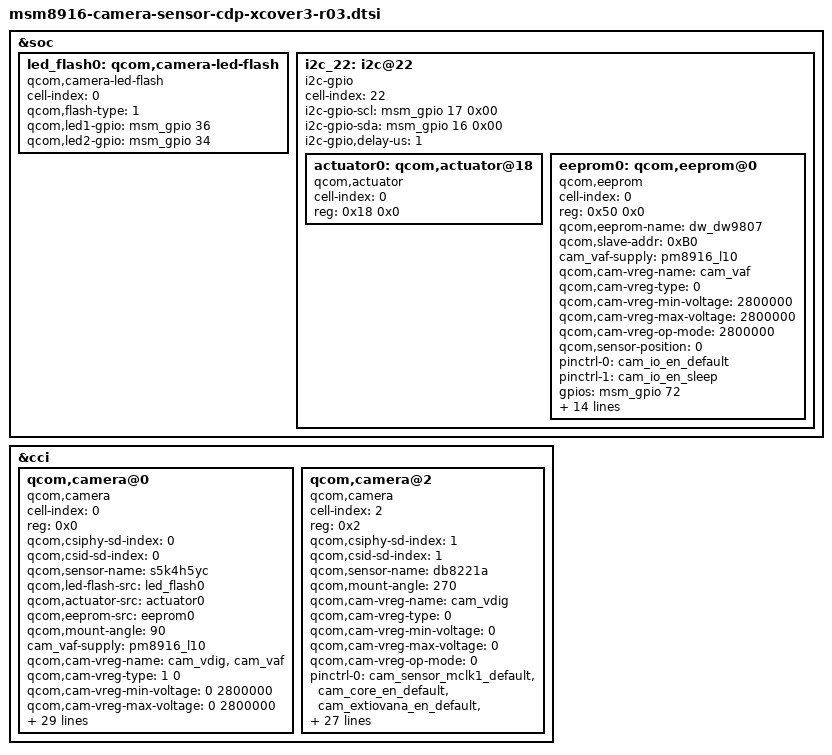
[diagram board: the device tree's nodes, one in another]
/*
 * Copyright (c) 2014, The Linux Foundation. All rights reserved.
 *
 * This program is free software; you can redistribute it and/or modify
 * it under the terms of the GNU General Public License version 2 and
 * only version 2 as published by the Free Software Foundation.
 *
 * This program is distributed in the hope that it will be useful,
 * but WITHOUT ANY WARRANTY; without even the implied warranty of
 * MERCHANTABILITY or FITNESS FOR A PARTICULAR PURPOSE.  See the
 * GNU General Public License for more details.
 */

&soc {
    led_flash0: qcom,camera-led-flash {
        cell-index = <0>;
        compatible = "qcom,camera-led-flash";
        qcom,flash-type = <1>;
        qcom,led1-gpio = <&msm_gpio 36 0x00>;
        qcom,led2-gpio = <&msm_gpio 34 0x00>;
    };

    i2c_22: i2c@22 {
        cell-index = <22>;
        compatible = "i2c-gpio";
        i2c-gpio-scl = <&msm_gpio 17 0x00>;
        i2c-gpio-sda = <&msm_gpio 16 0x00>;
        i2c-gpio,delay-us = <1>;

        actuator0: qcom,actuator@18 {
            compatible = "qcom,actuator";
            cell-index = <0>;
            reg = <0x18 0x0>;
        };

        eeprom0: qcom,eeprom@0 {
            compatible = "qcom,eeprom";
            cell-index = <0>;
            reg = <0x50 0x0>;
            qcom,eeprom-name = "dw_dw9807";
            qcom,slave-addr = <0xB0>;
            cam_vaf-supply = <&pm8916_l10>;
            qcom,cam-vreg-name = "cam_vaf";
            qcom,cam-vreg-type = <0>;
            qcom,cam-vreg-min-voltage = <2800000>;
            qcom,cam-vreg-max-voltage = <2800000>;
            qcom,cam-vreg-op-mode = <2800000>;
            qcom,sensor-position = <0>;
            pinctrl-names = "eeprom_default", "eeprom_suspend";
            pinctrl-0 = <&cam_io_en_default>;
            pinctrl-1 = <&cam_io_en_sleep>;
            gpios = <&msm_gpio 72 0>;
            qcom,gpio-vio = <0>;
            qcom,gpio-req-tbl-num = <0>;
            qcom,gpio-req-tbl-flags = <0>;
            qcom,gpio-req-tbl-label = "CAM_VIO";
            qcom,cam-power-seq-type = "sensor_vreg", "sensor_gpio";
            qcom,cam-power-seq-val =  "cam_vaf", "sensor_gpio_vio";
            qcom,cam-power-seq-cfg-val = <1 1>;
            qcom,cam-power-seq-delay = <1 1>;
            qcom,cal-num-blocks = <1>;
            qcom,cal-page0 = <0 0 0 0 0 0>;
            qcom,cal-poll0 = <0 0 0 0 0 0>;
            qcom,cal-mem0 = <0x1200 0x00 2 0 1 0>;
            status = "ok";
        };
    };
};

&cci {
    qcom,camera@0 {
        cell-index = <0>;
        compatible = "qcom,camera";
        reg = <0x0>;
        qcom,csiphy-sd-index = <0>;
        qcom,csid-sd-index = <0>;
        qcom,sensor-name = "s5k4h5yc";
        qcom,led-flash-src =<&led_flash0>;
        qcom,actuator-src = <&actuator0>;
        qcom,eeprom-src = <&eeprom0>;
        qcom,mount-angle = <90>;
        cam_vaf-supply = <&pm8916_l10>;
        qcom,cam-vreg-name = "cam_vdig","cam_vaf";
        qcom,cam-vreg-type = <1 0>;
        qcom,cam-vreg-min-voltage = <0 2800000>;
        qcom,cam-vreg-max-voltage = <0 2800000>;
        qcom,cam-vreg-op-mode = <0 0>;
        pinctrl-names = "cam_default", "cam_suspend";
        pinctrl-0 = <&cam_sensor_mclk0_default &cam_core_en_default &cam_extiovana_en_default &cam_sensor_rear_default>;
        pinctrl-1 = <&cam_sensor_mclk0_sleep &cam_core_en_sleep &cam_extiovana_en_sleep &cam_sensor_rear_sleep>;
        gpios = <&msm_gpio 26 0>,
            <&msm_gpio 35 0>,
            <&msm_gpio 72 0>,
            <&msm_gpio 112 0>;
        qcom,gpio-reset = <1>;
        qcom,gpio-ext-vio-power = <2>;
        qcom,gpio-ext-vana-power = <3>;
        qcom,gpio-req-tbl-num = <0 1 2 3>;
        qcom,gpio-req-tbl-flags = <1 0 0 0>;
        qcom,gpio-req-tbl-label = "CAMIF_MCLK",
            "CAM_RESET1",
            "CAM_IO_EN",
            "CAM_ANALOG_EN";
        qcom,sensor-position = <0>;
        qcom,sensor-mode = <0>;
        qcom,cci-master = <0>;
        status = "ok";
        clocks = <&clock_gcc clk_mclk0_clk_src>,
            <&clock_gcc clk_gcc_camss_mclk0_clk>;
        clock-names = "cam_src_clk", "cam_clk";
        cam,isp = <0>;              // 0 : INT , 1 : EXT , 2 : SOC
        cam,cal_memory = <2>;       // 0 : N , 1 : FROM , 2 : EEPROM , 3 : OTP
        cam,read_version = <0>;     // 0 : SYSFS , 1 : CAMON
        cam,core_voltage = <0>;     // 0 : N , 1 : Y
        cam,upgrade = <0>;          // 0 : N , 1 : SYSFS , 2 : CAMON
        cam,companion_chip = <0>;   // 0 : N , 1 : Y
        cam,ois = <0>;              // 0 : N , 1 : Y
    };

    qcom,camera@2 {
        cell-index = <2>;
        compatible = "qcom,camera";
        reg = <0x2>;
        qcom,csiphy-sd-index = <1>;
        qcom,csid-sd-index = <1>;
        qcom,sensor-name = "db8221a";
        qcom,mount-angle = <270>;
        qcom,cam-vreg-name = "cam_vdig";
        qcom,cam-vreg-type = <0>;
        qcom,cam-vreg-min-voltage = <0>;
        qcom,cam-vreg-max-voltage = <0>;
        qcom,cam-vreg-op-mode = <0>;
        pinctrl-names = "cam_default", "cam_suspend";
        pinctrl-0 = <&cam_sensor_mclk1_default &cam_core_en_default &cam_extiovana_en_default &cam_sensor_front_default>;
        pinctrl-1 = <&cam_sensor_mclk1_sleep &cam_core_en_sleep &cam_extiovana_en_sleep &cam_sensor_front_sleep>;
        gpios = <&msm_gpio 27 0>,
            <&msm_gpio 28 0>,
            <&msm_gpio 74 0>,
            <&msm_gpio 72 0>,
            <&msm_gpio 112 0>;
        qcom,gpio-vt-reset = <1>;
        qcom,gpio-vt-standby = <2>;
        qcom,gpio-ext-vio-power = <3>;
        qcom,gpio-ext-vana-power = <4>;
        qcom,gpio-req-tbl-num = <0 1 2 3 4>;
        qcom,gpio-req-tbl-flags = <1 0 0 0 0>;
        qcom,gpio-req-tbl-label = "CAMIF_MCLK",
            "CAM_RESET",
            "CAM_STBY",
            "CAM_IO_EN",
            "CAM_ANALOG_EN";
        qcom,sensor-position = <1>;
        qcom,sensor-mode = <0>;
        qcom,cci-master = <0>;
        status = "ok";
        clocks = <&clock_gcc clk_mclk1_clk_src>,
            <&clock_gcc clk_gcc_camss_mclk1_clk>;
        clock-names = "cam_src_clk", "cam_clk";
        cam,isp = <2>;              // 0 : INT , 1 : EXT , 2 : SOC
        cam,cal_memory = <0>;       // 0 : N , 1 : FROM , 2 : EEPROM , 3 : OTP
        cam,read_version = <0>;     // 0 : SYSFS , 1 : CAMON
        cam,core_voltage = <0>;     // 0 : N , 1 : Y
        cam,upgrade = <0>;          // 0 : N , 1 : SYSFS , 2 : CAMON
        cam,companion_chip = <0>;   // 0 : N , 1 : Y
        cam,ois = <0>;              // 0 : N , 1 : Y
    };
};
